# MM32F031xx register map
File version: 1.3
Registers are 32-bit, read-write, reset 0x0 unless marked. A register's access mark holds for its fields unless they carry their own. Offsets are from the block's base; [hi:lo] are bit positions; {n}, {i} and the like mark numbered series.

## SPI1 — Serial peripheral interface
Base 0x40013000
0x00 TXREG
  [31:0] TXREG — Transmit data register
0x04 RXREG ro
  [31:0] RXREG — Receive data register
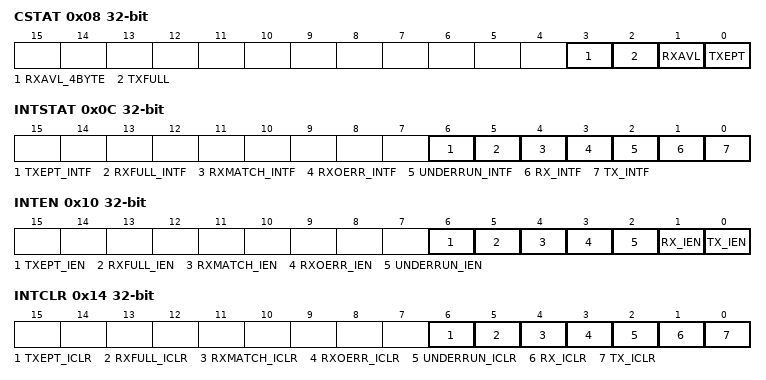
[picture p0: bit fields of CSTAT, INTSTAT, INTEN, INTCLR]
0x08 CSTAT ro
  [3] RXAVL_4BYTE — Receive available 4 byte data message
  [2] TXFULL — Transmitter FIFO full status bit
  [1] RXAVL — Receive available byte data message
  [0] TXEPT — Transmitter empty bit
0x0C INTSTAT
  [6] TXEPT_INTF — Transmitter empty interrupt flag bit
  [5] RXFULL_INTF — RX FIFO full interrupt flag bit
  [4] RXMATCH_INTF — "Receive data match the RXDNR number
  [3] RXOERR_INTF — Receive overrun error interrupt flag bit
  [2] UNDERRUN_INTF — SPI underrun interrupt flag bit
  [1] RX_INTF — Receive data available interrupt flag bit
  [0] TX_INTF — Transmit FIFO avialable interrupt flag bit
0x10 INTEN
  [6] TXEPT_IEN — Transmit empty interrupt enable bit
  [5] RXFULL_IEN — Receive FIFO full interrupt enable bit
  [4] RXMATCH_IEN — Receive data complete interrupt enable bit
  [3] RXOERR_IEN — Overrun error interrupt enable bit
  [2] UNDERRUN_IEN — Transmitter underrun interrupt enable bit(SPI slave mode only)
  [1] RX_IEN — Receive FIFO interrupt enable bit
  [0] TX_IEN — Transmit FIFO empty interrupt enable bit
0x14 INTCLR
  [6] TXEPT_ICLR — Transmitter empty interrupt clear bit
  [5] RXFULL_ICLR — Receiver buffer full interrupt clear bit
  [4] RXMATCH_ICLR — Receive completed interrupt clear bit
  [3] RXOERR_ICLR — Overrun error interrupt clear bit
  [2] UNDERRUN_ICLR — Transmitter underrun interrupt clear bit(SPI slave mode only)
  [1] RX_ICLR — Receive interrupt clear bit
  [0] TX_ICLR — Transmitter FIFO empty interrupt clear bit
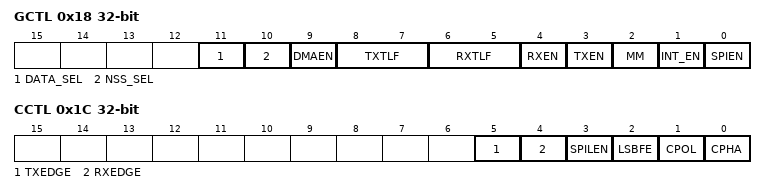
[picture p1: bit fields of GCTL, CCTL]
0x18 GCTL
  [11] DATA_SEL — Valid byte or double-word data select signal
  [10] NSS_SEL — NSS select signal that from software and hardware
  [9] DMAEN — DMA access mode enable
  [8:7] TXTLF — TX FIFO trigger level bit
  [6:5] RXTLF — RX FIFO trigger level bit
  [4] RXEN — Receive enable bit
  [3] TXEN — Transmit enable bit
  [2] MM — Master mode bit
  [1] INT_EN — SPI interrupt enable bit
  [0] SPIEN — SPI select bit
0x1C CCTL
  [5] TXEDGE — Transmit data edge select
  [4] RXEDGE — Receive data edge select
  [3] SPILEN — SPI character length bit
  [2] LSBFE — LSI first enable bit
  [1] CPOL — Clock polarity select bit
  [0] CPHA — Clock phase select bit
0x20 SPBRG
  [31:0] SPBRG — SPI baud rate control register for baud rate
0x24 RXDNR
  [31:0] RXDNR — The register is used to hold a count of to be received bytes in next receive process
0x28 NSSR
  [0] NSS — Chip select output signal in Master mode

## ADC — Analog to digital converter
Base 0x40012400
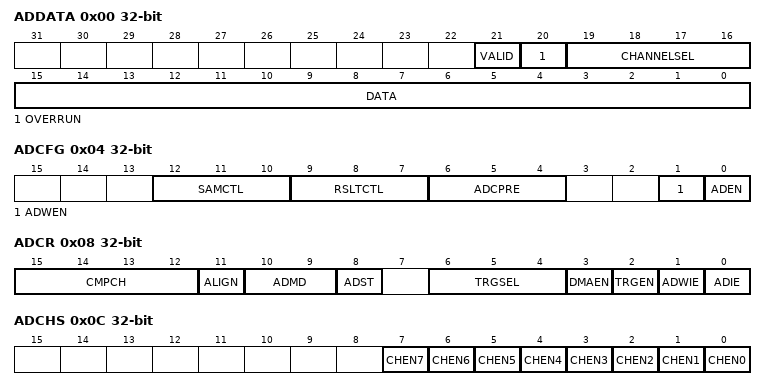
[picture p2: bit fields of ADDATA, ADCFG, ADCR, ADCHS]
0x00 ADDATA ro
  [21] VALID — Valid flag
  [20] OVERRUN — Overrun flag
  [19:16] CHANNELSEL — Channel selection
  [15:0] DATA — Transfer data
0x04 ADCFG
  [12:10] SAMCTL — Channel x Sample time selection
  [9:7] RSLTCTL — resolution
  [6:4] ADCPRE — ADC prescaler
  [1] ADWEN — ADC window comparison enable
  [0] ADEN — ADC enable
0x08 ADCR
  [15:12] CMPCH — Window comparison channel selection
  [11] ALIGN — Data alignment
  [10:9] ADMD — ADC mode
  [8] ADST — ADC start
  [6:4] TRGSEL — External trigger selection
  [3] DMAEN — Direct memory access enable
  [2] TRGEN — External trigger enable
  [1] ADWIE — ADC window comparator interrupt enable
  [0] ADIE — ADC interrupt enable
0x0C ADCHS
  [n] CHEN{n} (n=0..7) — Analog input channel {n} enable
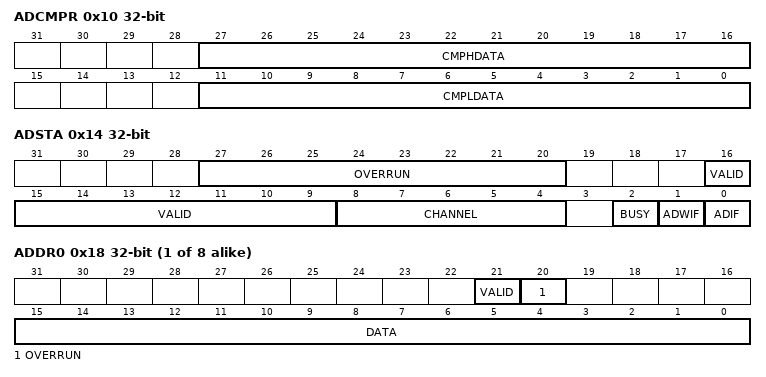
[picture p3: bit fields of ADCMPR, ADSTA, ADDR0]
0x10 ADCMPR
  [27:16] CMPHDATA — Compare data high limit
  [11:0] CMPLDATA — Compare data low limit
0x14 ADSTA ro
  [27:20] OVERRUN — Overrun flag
  [16:9] VALID — Valid flag
  [8:4] CHANNEL — Current conversion channel
  [2] BUSY
  [1] ADWIF — ADC window comparator interrupt flag
  [0] ADIF — ADC interrupt flag
{0x18+4i} ADDR{i} ro (i=0..7)
  [21] VALID — Valid flag
  [20] OVERRUN — Overrun flag
  [15:0] DATA — Transfer data
